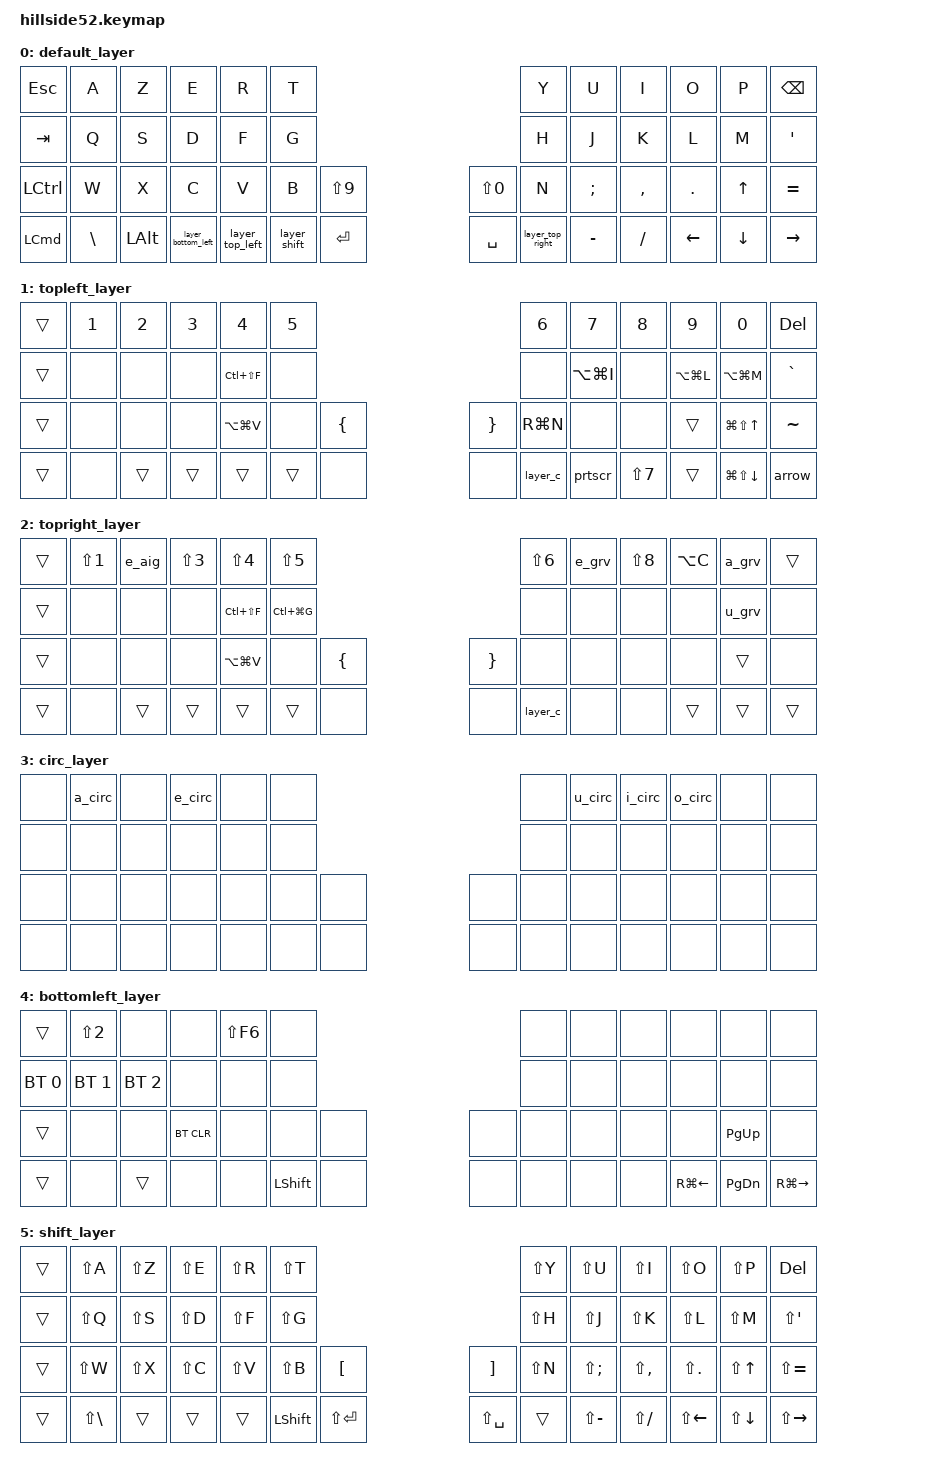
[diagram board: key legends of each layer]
/*
 * Copyright (c) 2021-2022 The ZMK Contributors
 *
 * SPDX-License-Identifier: MIT
 */

#include <behaviors.dtsi>
#include <dt-bindings/zmk/bt.h>
#include <dt-bindings/zmk/ext_power.h>
#include <dt-bindings/zmk/keys.h>
#include <dt-bindings/zmk/outputs.h>


/ {

chosen {
      zmk,battery = &vbatt;
    };

    vbatt: vbatt {
        compatible = "zmk,battery-nrf-vddh";
    };

macros {

    layer_top_left: layer_top_left {
	    compatible = "zmk,behavior-macro";
	    #binding-cells = <0>;
	    wait-ms = <0>;
	    tap-ms = <0>;
	    bindings
		= <&macro_press &mo 1>		
		, <&macro_pause_for_release>
		, <&macro_release &mo 1>
		;
	};
	
	layer_top_right: layer_top_right {
	    compatible = "zmk,behavior-macro";
	    #binding-cells = <0>;
	    wait-ms = <0>;
	    tap-ms = <0>;
	    bindings
		= <&macro_press &mo 2>		
		, <&macro_pause_for_release>
		, <&macro_release &mo 2>
		;
	};

layer_c: layer_c {
	    compatible = "zmk,behavior-macro";
	    #binding-cells = <0>;
	    wait-ms = <0>;
	    tap-ms = <0>;
	    bindings
		= <&macro_press &sl 3>		
		, <&macro_pause_for_release>
		, <&macro_release &sl 3>
		;
	};

layer_bottom_left: layer_bottom_left {
	    compatible = "zmk,behavior-macro";
	    #binding-cells = <0>;
	    wait-ms = <0>;
	    tap-ms = <0>;
	    bindings
		= <&macro_press &mo 4>
		, <&macro_pause_for_release>
		, <&macro_release &mo 4>
		;
	};

 layer_shift: layer_shift {
	    compatible = "zmk,behavior-macro";
	    #binding-cells = <2>;
	    wait-ms = <0>;
	    tap-ms = <0>;
	    bindings
		= <&macro_press &mo LSHIFT>
		, <&macro_press &lt 5>
		, <&macro_pause_for_release>
		, <&macro_release &lt 5>
        	, <&macro_release &mo LSHIFT>
		;
	};

e_aig: e_aig {
	    tap-ms = <50>;
            compatible = "zmk,behavior-macro";
            #binding-cells = <0>;
            bindings
                = <&macro_tap &kp LA(E)>
                , <&macro_tap &kp E>
                ;
        };
	
	a_grv: a_grv {
	    tap-ms = <50>;
            compatible = "zmk,behavior-macro";
            #binding-cells = <0>;
            bindings
                = <&macro_tap &kp LA(GRAVE)>
                , <&macro_tap &kp A>
                ;
        };
	
	a_circ: a_circ {
	    tap-ms = <50>;
            compatible = "zmk,behavior-macro";
            #binding-cells = <0>;
            bindings
                = <&macro_tap &kp LA(I)>
                , <&macro_tap &kp A>
                ;
        };

e_grv: e_grv {
	    tap-ms = <50>;
            compatible = "zmk,behavior-macro";
            #binding-cells = <0>;
            bindings
                = <&macro_tap &kp LA(GRAVE)>
                , <&macro_tap &kp E>
                ;
        };

c_ced: c_ced {
	    tap-ms = <50>;
            compatible = "zmk,behavior-macro";
            #binding-cells = <0>;
            bindings
                = <&macro_tap &kp LA(C)>
                ;
        };
	
	e_circ: e_circ {
	    tap-ms = <50>;
            compatible = "zmk,behavior-macro";
            #binding-cells = <0>;
            bindings
                = <&macro_tap &kp LA(I)>
                , <&macro_tap &kp E>
                ;
        };
	
	u_grv: u_grv {
	    tap-ms = <50>;
            compatible = "zmk,behavior-macro";
            #binding-cells = <0>;
            bindings
                = <&macro_tap &kp LA(GRAVE)>
                , <&macro_tap &kp U>
                ;
        };
	
	u_circ: u_circ {
	    tap-ms = <50>;
            compatible = "zmk,behavior-macro";
            #binding-cells = <0>;
            bindings
                = <&macro_tap &kp LA(I)>
                , <&macro_tap &kp U>
                ;
        };

o_circ: o_circ {
	    tap-ms = <50>;
            compatible = "zmk,behavior-macro";
            #binding-cells = <0>;
            bindings
                = <&macro_tap &kp LA(I)>
                , <&macro_tap &kp O>
                ;
        };
	
	i_circ: i_circ {
	    tap-ms = <50>;
            compatible = "zmk,behavior-macro";
            #binding-cells = <0>;
            bindings
                = <&macro_tap &kp LA(I)>
                , <&macro_tap &kp I>
                ;
        };

arrow: arrow {
	    tap-ms = <50>;
            compatible = "zmk,behavior-macro";
            #binding-cells = <0>;
            bindings
                = <&macro_tap &kp MINUS>
                , <&macro_tap &kp LS(DOT)>
                ;
        };

prtscr: prtscr {
	    tap-ms = <50>;
            compatible = "zmk,behavior-macro";
            #binding-cells = <0>;
            bindings
                = <&macro_tap &kp LCMD>
                , <&macro_tap &kp LS(N4)>
                ;
        };

    };



        keymap {
                compatible = "zmk,keymap";



                default_layer {
                        bindings = <
&kp  ESC    &kp  A          &kp  Z        &kp  E        &kp  R                  &kp  T                                                                                                &kp  Y        &kp  U            &kp  I        &kp  O         &kp  P                 &kp  BSPC
&kp  TAB    &kp  Q          &kp  S        &kp  D        &kp  F                  &kp  G                                                                                                &kp  H        &kp  J            &kp  K        &kp  L         &kp  M                 &kp  APOSTROPHE
&kp  LCTRL  &kp  W          &kp  X        &kp  C        &kp  V                  &kp  B               &kp  LS(N9)                                                &kp  LS(N0)           &kp  N        &kp  SEMICOLON    &kp  COMMA    &kp  DOT       &kp  UP                &kp  EQUAL
&kp  LCMD   &kp  BACKSLASH  &kp  LALT                   &layer_bottom_left      &layer_top_left      &layer_shift       &kp  ENTER            &kp  SPACE        &layer_top_right      &kp  MINUS    &kp  SLASH                      &kp  LEFT      &kp  DOWN              &kp  RIGHT
                        >;
			
                };

                topleft_layer {
                        bindings = <
&trans      &kp  N1         &kp  N2       &kp  N3      &kp  N4                  &kp  N5                                                                                               &kp  N6       &kp  N7           &kp  N8       &kp  N9         &kp  N0                &kp  DELETE
&trans      &none           &none         &none        &kp  LC(LS(F))           &none                                                                                                 &none         &kp LA(LG(I))     &none         &kp LA(LG(L))   &kp LA(LG(M))          &kp  GRAVE
&trans      &none           &none         &none        &kp  LA(LG(V))           &none                &kp LBRC                                                   &kp RBRC              &kp RG(N)     &none             &none         &trans          &kp LG(LS(UP))         &kp  TILDE
&trans      &none           &trans                     &trans                   &trans               &trans             &none                 &none             &layer_c              &prtscr         &kp LS(N7)                      &trans          &kp LG(LS(DOWN))       &arrow
                        >;			
                };

                topright_layer {
                        bindings = <
&trans      &kp  LS(N1)     &e_aig        &kp  LS(N3)  &kp  LS(N4)             &kp  LS(N5)                                                                                           &kp  LS(N6)    &e_grv           &kp LS(N8)     &kp  LA(C)     &a_grv                 &trans
&trans      &none           &none         &none        &kp  LC(LS(F))          &kp  LC(LG(G))                                                                                        &none          &none            &none          &none          &u_grv                 &none
&trans      &none           &none         &none        &kp  LA(LG(V))          &none                 &kp LBRC                                                   &kp RBRC             &none          &none            &none          &none          &trans                 &none
&trans      &none           &trans                     &trans                  &trans                &trans             &none                 &none             &layer_c             &none          &none                           &trans         &trans                 &trans
                        >;
                };

                circ_layer {
                        bindings = <
&none      &a_circ     &none       &e_circ     &none       &none                                                                &none      &u_circ    &i_circ      &o_circ    &none       &none
&none      &none       &none       &none       &none       &none                                                                &none      &none      &none        &none      &none       &none
&none      &none       &none       &none       &none       &none       &none                                         &none      &none      &none      &none        &none      &none       &none
&none      &none       &none                   &none       &none       &none        &none                 &none      &none      &none      &none                   &none      &none       &none
                        >;
                };

		bottomleft_layer {
                        bindings = <  
&trans         &kp LS(N2)            &none              &none                 &kp LS(F6)            &none                                                                                    &none            &none                  &none               &none             &none             &none
&bt BT_SEL 0     &bt BT_SEL 1          &bt BT_SEL 2       &none          &none            &none                                                                                    &none            &none                  &none               &none             &none             &none
&trans         &none                 &none              &bt BT_CLR            &none            &none          &none                                                     &none           &none            &none                  &none               &none             &kp PG_UP         &none
&trans         &none                 &trans                                   &none            &none          &kp LSHIFT        &none                  &none            &none           &none            &none                                      &kp RG(LEFT)      &kp PG_DN         &kp RG(RIGHT)
                        >;
                };

		shift_layer {
                        bindings = <
&trans        &kp  LS(A)            &kp  LS(Z)         &kp  LS(E)            &kp  LS(R)        &kp  LS(T)                                                                               &kp  LS(Y)        &kp  LS(U)            &kp  LS(I)          &kp  LS(O)        &kp  LS(P)        &kp  DELETE
&trans        &kp  LS(Q)            &kp  LS(S)         &kp  LS(D)            &kp  LS(F)        &kp  LS(G)                                                                               &kp  LS(H)        &kp  LS(J)            &kp  LS(K)          &kp  LS(L)        &kp  LS(M)        &kp  LS(APOSTROPHE)
&trans        &kp  LS(W)            &kp  LS(X)         &kp  LS(C)            &kp  LS(V)        &kp  LS(B)     &kp  LBKT                                                 &kp  RBKT       &kp  LS(N)        &kp  LS(SEMICOLON)    &kp  LS(COMMA)      &kp  LS(DOT)      &kp  LS(UP)       &kp  LS(EQUAL)
&trans        &kp  LS(BACKSLASH)    &trans                                   &trans            &trans         &kp  LSHIFT       &kp  LS(ENTER)         &kp LS(SPACE)    &trans          &kp  LS(MINUS)    &kp  LS(SLASH)                            &kp  LS(LEFT)     &kp  LS(DOWN)     &kp  LS(RIGHT)
                        >;
                };
               
        };
};
